AUTOSAR XML (schema 00053)
package /Application
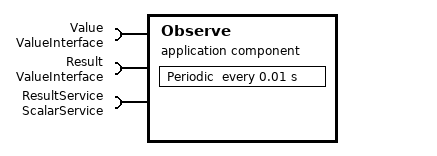
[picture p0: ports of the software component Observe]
  application sw component type Observe
    require port Value: nonqueued-receiver-com-spec{data-element=Value, init-value=9}, required-interface=ValueInterface
    require port Result: nonqueued-receiver-com-spec{data-element=Value, init-value=11}, required-interface=ValueInterface
    require port ResultService: client-com-spec=Transform, required-interface=ScalarService
    behavior Behavior: data-type-mapping=ApplicationTypes
      timing event Periodic10ms: start-on-event=Periodic, period=0.01
      runnable Periodic: symbol=Observe_Periodic
        data-receive-point-by-arguments:
          access RValue: accessed-variable=Value.Value
          access RResult: accessed-variable=Result.Value
        sync call CallTransform: operation=ResultService.Transform
